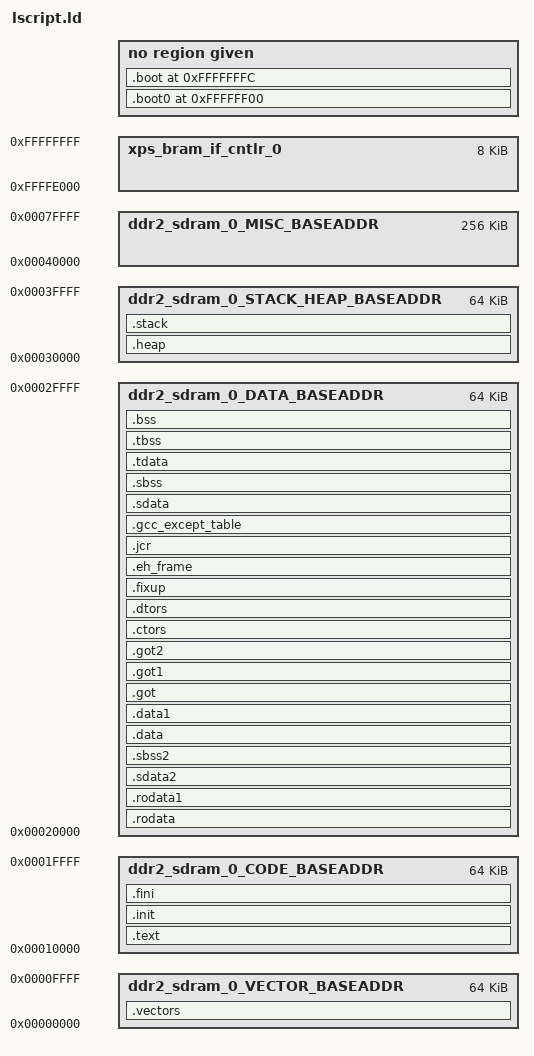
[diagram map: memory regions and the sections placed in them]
/*******************************************************************/
/*                                                                 */
/* This file is automatically generated by linker script generator.*/
/*                                                                 */
/* Version: Xilinx EDK 12.4 EDK_MS4.81d                            */
/*                                                                 */
/* Copyright (c) 2010 Xilinx, Inc.  All rights reserved.           */
/*                                                                 */
/* Description : PowerPC440 Linker Script                          */
/*                                                                 */
/*******************************************************************/

_STACK_SIZE = DEFINED(_STACK_SIZE) ? _STACK_SIZE : 0x8000;
_HEAP_SIZE = DEFINED(_HEAP_SIZE) ? _HEAP_SIZE : 0x8000;

/* Define Memories in the system */
/* lingkang: i use seperate MEMORY for .vector */
/* lingkang: i only use 16MB memory */

MEMORY
{
   xps_bram_if_cntlr_0 : ORIGIN = 0xFFFFE000, LENGTH = 0x00002000
   ddr2_sdram_0_VECTOR_BASEADDR : ORIGIN = 0x00000000, LENGTH = 0x00010000
   ddr2_sdram_0_CODE_BASEADDR : ORIGIN = 0x00010000, LENGTH = 0x00010000
   ddr2_sdram_0_DATA_BASEADDR : ORIGIN = 0x00020000, LENGTH = 0x00010000
   ddr2_sdram_0_STACK_HEAP_BASEADDR : ORIGIN = 0x00030000, LENGTH = 0x00010000
   ddr2_sdram_0_MISC_BASEADDR : ORIGIN = 0x00040000, LENGTH = 0x00040000
}

/* Specify the default entry point to the program */

ENTRY(_boot)
STARTUP(boot.o)

/* Define the sections, and where they are mapped in memory */

SECTIONS
{

/* Generate Interrupt Vector Sections */

.vectors : {
   __vectors_start = .;
   *(.vectors)
   __vectors_end = .;
} > ddr2_sdram_0_VECTOR_BASEADDR

/* Generate Code Sections */

.text : {
   *(.text)
   *(.text.*)
   *(.gnu.linkonce.t.*)
} > ddr2_sdram_0_CODE_BASEADDR

.init : {
   KEEP (*(.init))
} > ddr2_sdram_0_CODE_BASEADDR

.fini : {
   KEEP (*(.fini))
} > ddr2_sdram_0_CODE_BASEADDR

/* Generate Data Sections */

.rodata : {
   __rodata_start = .;
   *(.rodata)
   *(.rodata.*)
   *(.gnu.linkonce.r.*)
   __rodata_end = .;
} > ddr2_sdram_0_DATA_BASEADDR

.rodata1 : {
   __rodata1_start = .;
   *(.rodata1)
   *(.rodata1.*)
   __rodata1_end = .;
} > ddr2_sdram_0_DATA_BASEADDR

.sdata2 : {
   __sdata2_start = .;
   *(.sdata2)
   *(.sdata2.*)
   *(.gnu.linkonce.s2.*)
   __sdata2_end = .;
} > ddr2_sdram_0_DATA_BASEADDR

.sbss2 : {
   __sbss2_start = .;
   *(.sbss2)
   *(.sbss2.*)
   *(.gnu.linkonce.sb2.*)
   __sbss2_end = .;
} > ddr2_sdram_0_DATA_BASEADDR

.data : {
   __data_start = .;
   *(.data)
   *(.data.*)
   *(.gnu.linkonce.d.*)
   __data_end = .;
} > ddr2_sdram_0_DATA_BASEADDR

.data1 : {
   __data1_start = .;
   *(.data1)
   *(.data1.*)
   __data1_end = .;
} > ddr2_sdram_0_DATA_BASEADDR

.got : {
   *(.got)
} > ddr2_sdram_0_DATA_BASEADDR

.got1 : {
   *(.got1)
} > ddr2_sdram_0_DATA_BASEADDR

.got2 : {
   *(.got2)
} > ddr2_sdram_0_DATA_BASEADDR

.ctors : {
   __CTOR_LIST__ = .;
   ___CTORS_LIST___ = .;
   KEEP (*crtbegin.o(.ctors))
   KEEP (*(EXCLUDE_FILE(*crtend.o) .ctors))
   KEEP (*(SORT(.ctors.*)))
   KEEP (*(.ctors))
   __CTOR_END__ = .;
   ___CTORS_END___ = .;
} > ddr2_sdram_0_DATA_BASEADDR

.dtors : {
   __DTOR_LIST__ = .;
   ___DTORS_LIST___ = .;
   KEEP (*crtbegin.o(.dtors))
   KEEP (*(EXCLUDE_FILE(*crtend.o) .dtors))
   KEEP (*(SORT(.dtors.*)))
   KEEP (*(.dtors))
   __DTOR_END__ = .;
   ___DTORS_END___ = .;
} > ddr2_sdram_0_DATA_BASEADDR

.fixup : {
   __fixup_start = .;
   *(.fixup)
   __fixup_end = .;
} > ddr2_sdram_0_DATA_BASEADDR

.eh_frame : {
   *(.eh_frame)
} > ddr2_sdram_0_DATA_BASEADDR

.jcr : {
   *(.jcr)
} > ddr2_sdram_0_DATA_BASEADDR

.gcc_except_table : {
   *(.gcc_except_table)
} > ddr2_sdram_0_DATA_BASEADDR

.sdata : {
   __sdata_start = .;
   *(.sdata)
   *(.sdata.*)
   *(.gnu.linkonce.s.*)
   __sdata_end = .;
} > ddr2_sdram_0_DATA_BASEADDR

.sbss : {
   __sbss_start = .;
   *(.sbss)
   *(.sbss.*)
   *(.gnu.linkonce.sb.*)
   *(.scommon)
   __sbss_end = .;
} > ddr2_sdram_0_DATA_BASEADDR

.tdata : {
   __tdata_start = .;
   *(.tdata)
   *(.tdata.*)
   *(.gnu.linkonce.td.*)
   __tdata_end = .;
} > ddr2_sdram_0_DATA_BASEADDR

.tbss : {
   __tbss_start = .;
   *(.tbss)
   *(.tbss.*)
   *(.gnu.linkonce.tb.*)
   __tbss_end = .;
} > ddr2_sdram_0_DATA_BASEADDR

.bss : {
   __bss_start = .;
   *(.bss)
   *(.bss.*)
   *(.gnu.linkonce.b.*)
   *(COMMON)
   . = ALIGN(4);
   __bss_end = .;
} > ddr2_sdram_0_DATA_BASEADDR

/* Generate Stack and Heap Sections */

.heap : {
   . = ALIGN(0x8000);
   _heap_start = .;
   . += _HEAP_SIZE;
   . = ALIGN(0x8000);
   _heap_end = .;
   _end = .;
} > ddr2_sdram_0_STACK_HEAP_BASEADDR

.stack : {
   _stack_end = .;
   . += _STACK_SIZE;
   . = ALIGN(0x8000);
   __stack = .;
} > ddr2_sdram_0_STACK_HEAP_BASEADDR

/* Generate Boot Sections (BRAM) */

.boot0 0xFFFFFF00 : {
   __boot0_start = .;
   *(.boot0)
   __boot0_end = .;
} 

.boot 0xFFFFFFFC : {
   __boot_start = .;
   *(.boot)
   __boot_end = .;
} 

}

